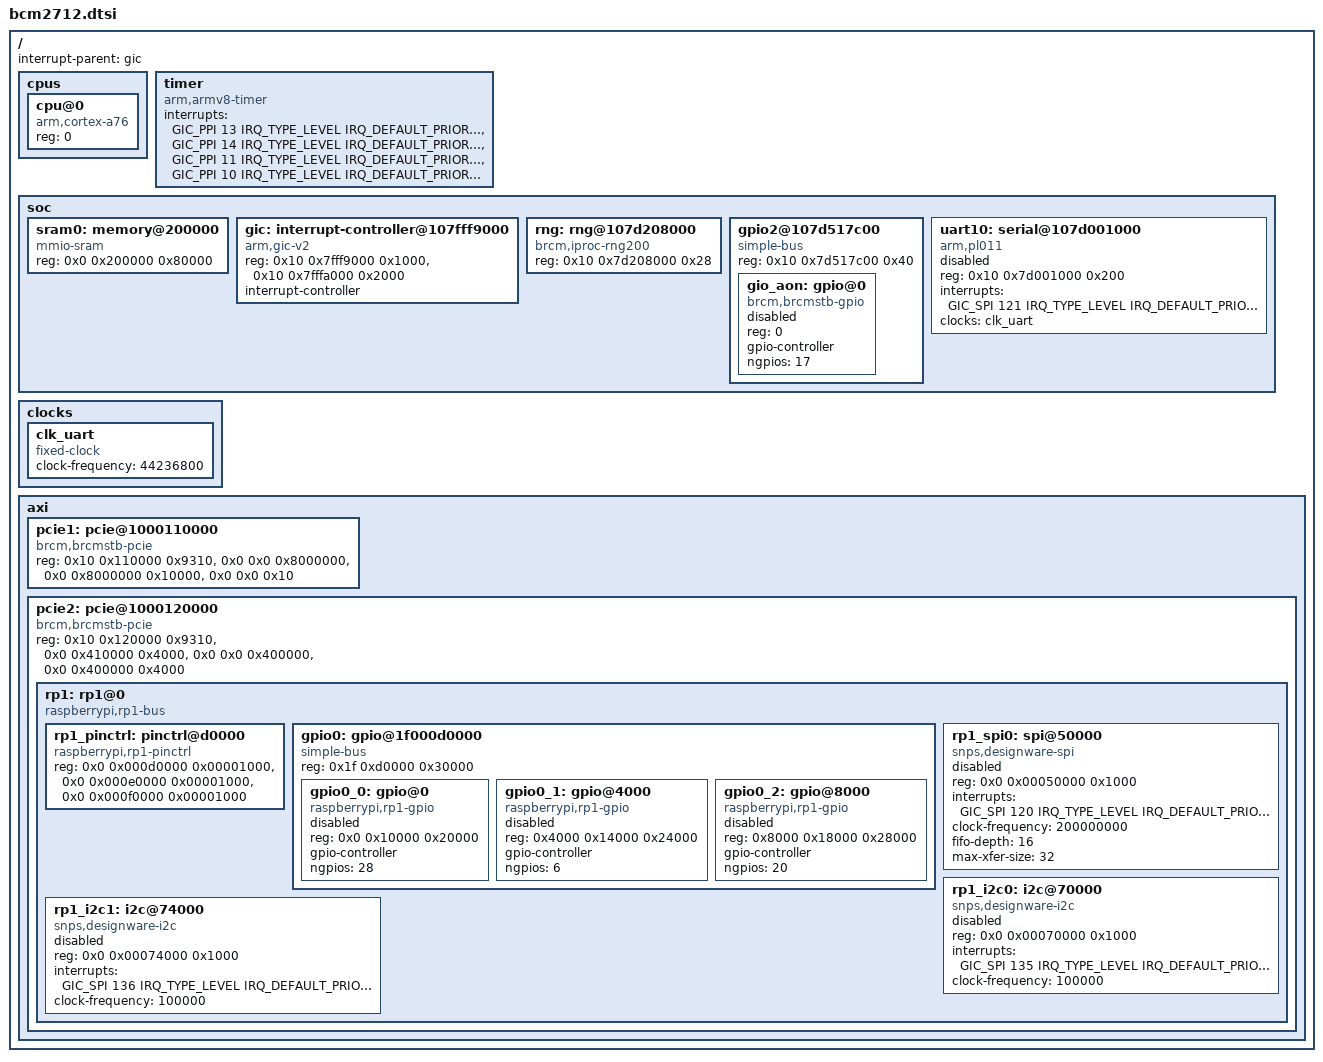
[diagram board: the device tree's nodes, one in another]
/*
 * Copyright 2024 Myeonghyeon Park <myeonghyeon@tsnlab.com>
 *
 * SPDX-License-Identifier: Apache-2.0
 */

#include <arm64/armv8-a.dtsi>
#include <zephyr/dt-bindings/interrupt-controller/arm-gic.h>
#include <zephyr/dt-bindings/pcie/pcie.h>

/ {
    cpus {
        #address-cells = <1>;
        #size-cells = <0>;

        cpu@0 {
            device_type = "cpu";
            compatible = "arm,cortex-a76";
            reg = <0>;
        };
    };

    interrupt-parent = <&gic>;

    timer {
        compatible = "arm,armv8-timer";
        interrupts = <GIC_PPI 13 IRQ_TYPE_LEVEL
                      IRQ_DEFAULT_PRIORITY>,
                     <GIC_PPI 14 IRQ_TYPE_LEVEL
                      IRQ_DEFAULT_PRIORITY>,
                     <GIC_PPI 11 IRQ_TYPE_LEVEL
                      IRQ_DEFAULT_PRIORITY>,
                     <GIC_PPI 10 IRQ_TYPE_LEVEL
                      IRQ_DEFAULT_PRIORITY>;
    };

    soc {
        #address-cells = <2>;
        #size-cells = <1>;

        sram0: memory@200000 {
            device_type = "memory";
            compatible = "mmio-sram";
            reg = <0x0 0x200000 0x80000>;
        };

        gic: interrupt-controller@107fff9000 {
            compatible = "arm,gic-v2", "arm,gic";
            reg = <0x10 0x7fff9000 0x1000>,
                  <0x10 0x7fffa000 0x2000>;
            interrupt-controller;
            #interrupt-cells = <4>;
            status = "okay";
        };

        rng: rng@107d208000 {
            compatible = "brcm,iproc-rng200";
            reg = <0x10 0x7d208000 0x28>;
            status = "okay";
        };

        gpio2@107d517c00 {
            compatible = "simple-bus";
            reg = <0x10 0x7d517c00 0x40>;

            #address-cells = <1>;
            #size-cells = <0>;

            gio_aon: gpio@0 {
                compatible = "brcm,brcmstb-gpio";
                reg = <0>;
                gpio-controller;
                #gpio-cells = <2>;
                ngpios = <17>;
                status = "disabled";
            };
        };

        uart10: serial@107d001000 {
            compatible = "arm,pl011";
            reg = <0x10 0x7d001000 0x200>;
            interrupts = <GIC_SPI 121 IRQ_TYPE_LEVEL
                          IRQ_DEFAULT_PRIORITY>;
            interrupt-names = "irq_121";
            clocks = <&clk_uart>;
            status = "disabled";
        };
    };

    clocks {
        clk_uart: clk_uart {
            compatible = "fixed-clock";
            clock-frequency = <44236800>;
            #clock-cells = <0>;
        };
    };

    axi {
        #address-cells = <2>;
        #size-cells = <1>;

        pcie1: pcie@1000110000 {
            compatible = "brcm,brcmstb-pcie";
            reg = <0x10 0x110000 0x9310>,
                  <0x0 0x0 0x8000000>,
                  <0x0 0x8000000 0x10000>,
                  <0x0 0x0 0x10>;
            #address-cells = <3>;
            #size-cells = <2>;
            status = "okay";
            ranges = <0x02000000 0x0 0x0 0x1b 0x0 0x00 0xfffffffc>,
                     <0x43000000 0x4 0x0 0x18 0x0 0x03 0x00000000>,
                     <0x03000000 0x0 0x0 0x10 0x0 0x10 0x00000000>;
        };

        pcie2: pcie@1000120000 {
            compatible = "brcm,brcmstb-pcie";
            reg = <0x10 0x120000 0x9310>,
                  <0x0 0x410000 0x4000>,
                  <0x0 0x0 0x400000>,
                  <0x0 0x400000 0x4000>;
            #address-cells = <3>;
            #size-cells = <2>;
            ranges = <0x02000000 0x0 0x0 0x1f 0x0 0x00 0xfffffffc>,
                     <0x43000000 0x4 0x0 0x1c 0x0 0x03 0x00000000>,
                     <0x02000000 0x0 0x0 0x1f 0x0 0x00 0x00400000>;
            status = "okay";

			rp1: rp1@0 {
				// compatible = "simple-bus";
				compatible = "raspberrypi,rp1-bus", "simple-bus";
				#address-cells = <2>;
				#size-cells = <1>;
				ranges = <0x0 0x0 0x0 0x1f 0x00000000 0x01000000>;

                rp1_pinctrl: pinctrl@d0000 {
						compatible = "raspberrypi,rp1-pinctrl";
						reg = <0x0 0x000d0000 0x00001000>,
							<0x0 0x000e0000 0x00001000>,
							<0x0 0x000f0000 0x00001000>;
						status = "okay";
					};


                gpio0: gpio@1f000d0000 {
                    compatible = "simple-bus";
                    reg = <0x1f 0xd0000 0x30000>;
                    #address-cells = <1>;
                    #size-cells = <0>;

                    gpio0_0: gpio@0 {
                        compatible = "raspberrypi,rp1-gpio";
                        reg = <0x0 0x10000 0x20000>;
                        #gpio-cells = <2>;
                        gpio-controller;
                        ngpios = <28>;
                        status = "disabled";
                    };

                    gpio0_1: gpio@4000 {
                        compatible = "raspberrypi,rp1-gpio";
                        reg = <0x4000 0x14000 0x24000>;
                        #gpio-cells = <2>;
                        gpio-controller;
                        ngpios = <6>;
                        status = "disabled";
                    };

                    gpio0_2: gpio@8000 {
                        compatible = "raspberrypi,rp1-gpio";
                        reg = <0x8000 0x18000 0x28000>;
                        #gpio-cells = <2>;
                        gpio-controller;
                        ngpios = <20>;
                        status = "disabled";
                    };
                };

				/* =========================
		 		* RP1 SPI0 (DesignWare SPI)
		 		* ========================= */
				rp1_spi0: spi@50000 {
					compatible = "snps,designware-spi";
					reg = <0x0 0x00050000 0x1000>;
					interrupts = <GIC_SPI 120 IRQ_TYPE_LEVEL IRQ_DEFAULT_PRIORITY>;

					#address-cells = <1>;
					#size-cells = <0>;

					clock-frequency = <200000000>;
					fifo-depth = <16>;
					max-xfer-size = <32>;

					status = "disabled";
				};

				/* =========================
				* RP1 I2C0 (DesignWare I2C)
				* ========================= */
				rp1_i2c0: i2c@70000 {
					compatible = "snps,designware-i2c";
					reg = <0x0 0x00070000 0x1000>;

					interrupts = <GIC_SPI 135 IRQ_TYPE_LEVEL IRQ_DEFAULT_PRIORITY>;

					#address-cells = <1>;
					#size-cells = <0>;

					/* Standard-mode default (100kHz) */
					clock-frequency = <100000>;

					status = "disabled";
				};

				rp1_i2c1: i2c@74000 {
					compatible = "snps,designware-i2c";
					reg = <0x0 0x00074000 0x1000>;

					interrupts = <GIC_SPI 136 IRQ_TYPE_LEVEL IRQ_DEFAULT_PRIORITY>;

					#address-cells = <1>;
					#size-cells = <0>;

					clock-frequency = <100000>;

					status = "disabled";
				};
			};
		};
	};
};
